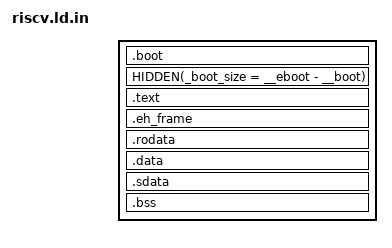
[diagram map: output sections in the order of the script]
/* Linker scripts are documented here:
 * https://sourceware.org/binutils/docs/ld/Scripts.html */
OUTPUT_ARCH(riscv)
ENTRY(_start)

PHDRS
{
  boot   PT_LOAD FLAGS(5); /* read-only, executable */
  text   PT_LOAD FLAGS(5); /* read-only, executable */
  rodata PT_LOAD FLAGS(4); /* read-only */
  data   PT_LOAD FLAGS(6); /* read-write */
}

SECTIONS
{
  .boot _KERNEL_PHYS : AT(_KERNEL_PHYS) ALIGN(4096)
  {
    __boot = ABSOLUTE(.);
    KEEP(*(.boot))
    *(.boot.text)
    *(.boot.data)
    . = ALIGN(4096);
    __eboot = ABSOLUTE(.);
  } : boot

  HIDDEN(_boot_size = __eboot - __boot);

  .text _KERNEL_VIRT + _boot_size : AT(__eboot) ALIGN(4096)
  {
    __kernel_start = ABSOLUTE(.);
    __kernel_start_pa = LOADADDR(.text);
    __text = ABSOLUTE(.);
    __text_pa = LOADADDR(.text);
    __riscv_boot_pa = LOADADDR(.text);
    *(.text.riscv_boot)
    *(.text .text.*)
    __etext = ABSOLUTE(.);
    /* Constructors are used by KASAN to initialize global redzones */
    __CTOR_LIST__ = ABSOLUTE(.);
    *(.ctors)
    __CTOR_END__ = ABSOLUTE(.);
  } : text

  .eh_frame : { *(.eh_frame) }

  .rodata :
  {
    *(.rodata .rodata.*)
  } : rodata

  .data : ALIGN(4096)
  {
    __data = ABSOLUTE(.);
    __data_pa = LOADADDR(.data);
    *(.data .data.*)
  } : data

  /* We use linker relaxations based on `__global_pointer$` for `.sdata`.
   * For unknown reason `ld` cannot apply relaxation to `.sbss`.
   * Relaxation is useless for code referring to `.srodata` since the data
   * is too far away from `gp` to be addressed using only 12 bits. Thus small
   * sections other than `.sdata` are merged into their large counterparts.
   *
   * Refer to following blog post to understand what linker relaxations are:
   * https://www.sifive.com/blog/all-aboard-part-3-linker-relaxation-in-riscv-toolchain */

  .sdata :
  {
    /* Load/store instruction offset is 12 bits (sign extended). */
    __global_pointer$ = . + 0x800;
    __global_pointer$_pa = LOADADDR(.sdata) + 0x800;
    *(.srodata .srodata.*)
    *(.sdata .sdata.*)
    __edata = ABSOLUTE(.);
  } : data

  .bss :
  {
    __bss = ABSOLUTE(.);
    __boot_stack_pa = LOADADDR(.bss);
    *(.bss.boot_stack)
    *(.sbss .sbss.*)
    *(.scommon)
    *(.bss .bss.*)
    *(COMMON)
    __ebss = ABSOLUTE(.);
    __ebss_pa = LOADADDR(.bss) + SIZEOF(.bss);
    __kernel_end = ABSOLUTE(.);
    __kernel_end_pa = LOADADDR(.bss) + SIZEOF(.bss);
  }

  /* Sections to be discarded. */
  /DISCARD/ :
  {
    *(.comment)
    *(.gnu.attributes)
    *(.note .note.*)
    *(.options)
    *(.pdr)
    *(.reginfo)
  }
}
